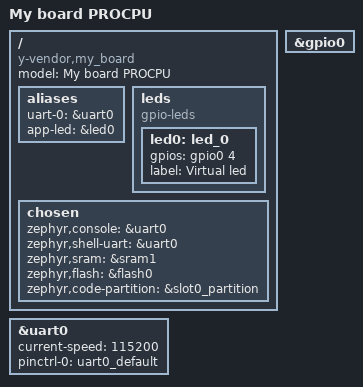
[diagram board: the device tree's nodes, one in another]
/dts-v1/;

#include <espressif/esp32/esp32_wrover_e_n4r8.dtsi>
#include "esp32_devkitc-pinctrl.dtsi"
#include <espressif/partitions_0x1000_amp.dtsi>

/ {
	model = "My board PROCPU";
	compatible = "y-vendor,my_board";

	aliases {
		uart-0 = &uart0;
		app-led = &led0;
	};

	leds {
		compatible = "gpio-leds";
		led0: led_0 {
			gpios = <&gpio0 4 GPIO_ACTIVE_HIGH>;
			label = "Virtual led";
		};
	};

	chosen {
		zephyr,console = &uart0;
		zephyr,shell-uart = &uart0;
		zephyr,sram = &sram1;
		zephyr,flash = &flash0;
		zephyr,code-partition = &slot0_partition;
	};
};

&uart0 {
	status = "okay";
	current-speed = <115200>;
	pinctrl-0 = <&uart0_default>;
	pinctrl-names = "default";
};

&gpio0 {
	status = "okay";
};

